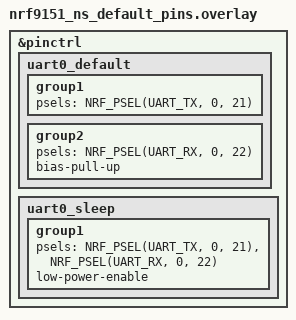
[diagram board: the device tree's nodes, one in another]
/*
 * MTIB REV 1.2 UART pin confirmation — nRF9151 (Alpha B0).
 *
 * Explicitly sets UART0 pin assignments to base DTS defaults.
 * Used to suppress auto-discovery of pin-swap overlays for REV 1.2 builds.
 *
 * Pins: TX=P0.21, RX=P0.22 (base DTS defaults)
 *
 * Apply via: -DDTC_OVERLAY_FILE="overlays/nrf9151_ns_default_pins.overlay"
 */

&pinctrl {
    uart0_default: uart0_default {
        group1 {
            psels = <NRF_PSEL(UART_TX, 0, 21)>;
        };
        group2 {
            psels = <NRF_PSEL(UART_RX, 0, 22)>;
            bias-pull-up;
        };
    };

    uart0_sleep: uart0_sleep {
        group1 {
            psels = <NRF_PSEL(UART_TX, 0, 21)>,
                    <NRF_PSEL(UART_RX, 0, 22)>;
            low-power-enable;
        };
    };
};
